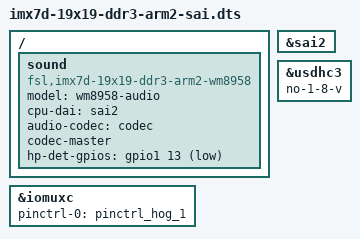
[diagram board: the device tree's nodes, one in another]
/*
 * Copyright (C) 2015 Freescale Semiconductor, Inc.
 *
 * This program is free software; you can redistribute it and/or modify
 * it under the terms of the GNU General Public License version 2 as
 * published by the Free Software Foundation.
 */

#include "imx7d-19x19-ddr3-arm2.dts"

/ {
	sound {
		compatible = "fsl,imx7d-19x19-ddr3-arm2-wm8958",
			   "fsl,imx-audio-wm8958";
		model = "wm8958-audio";
		cpu-dai = <&sai2>;
		audio-codec = <&codec>;
		codec-master;
		hp-det-gpios = <&gpio1 13 1>;
	};
};

&iomuxc {
	pinctrl-0 = <&pinctrl_hog_1>;
};

&sai2 {
	status = "okay";
};

&usdhc3 {
	no-1-8-v;
};
